# APM32F070 register map
File version: 1.0
Registers are 32-bit, read-write, reset 0x0 unless marked. A register's access mark holds for its fields unless they carry their own. Offsets are from the block's base; [hi:lo] are bit positions; {n}, {i} and the like mark numbered series.

## TMR6 — Basic-timers
Base 0x40001000
Same registers: TMR7 0x40001400
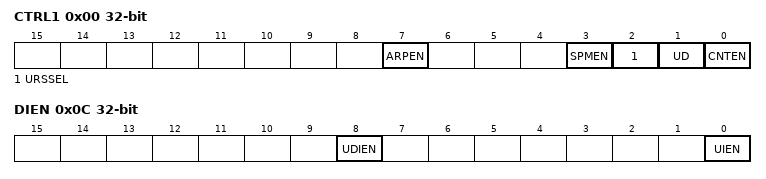
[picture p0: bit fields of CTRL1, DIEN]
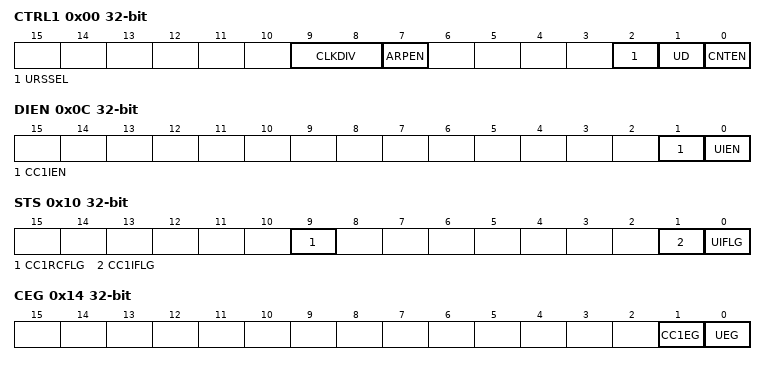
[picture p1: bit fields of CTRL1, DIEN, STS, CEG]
0x00 CTRL1 — control register 1
  [7] ARPEN — Auto-reload preload enable
  [3] SPMEN — One-pulse mode
  [2] URSSEL — Update request source
  [1] UD — Update disable
  [0] CNTEN — Counter enable
0x04 CTRL2 — control register 2
  [6:4] MMSEL — Master mode selection
0x0C DIEN — DMA/Interrupt enable register
  [8] UDIEN — Update DMA request enable
  [0] UIEN — Update interrupt enable
0x10 STS — status register
  [0] UIFLG — Update interrupt flag
0x14 CEG wo — event generation register
  [0] UEG — Update generation
0x24 CNT — counter
  [15:0] CNT — Low counter value
0x28 PSC — prescaler
  [15:0] PSC — Prescaler value
0x2C AUTORLD reset 0xFFFF — auto-reload register
  [15:0] AUTORLD — Low Auto-reload value

## TMR14 — General-purpose-timers
Base 0x40002000
0x00 CTRL1 — control register 1
  [9:8] CLKDIV — Clock division
  [7] ARPEN — Auto-reload preload enable
  [2] URSSEL — Update request source
  [1] UD — Update disable
  [0] CNTEN — Counter enable
0x0C DIEN — DMA/Interrupt enable register
  [1] CC1IEN — Capture/Compare 1 interrupt enable
  [0] UIEN — Update interrupt enable
0x10 STS — status register
  [9] CC1RCFLG — Capture/Compare 1 overcapture flag
  [1] CC1IFLG — Capture/compare 1 interrupt flag
  [0] UIFLG — Update interrupt flag
0x14 CEG wo — event generation register
  [1] CC1EG — Capture/compare 1 generation
  [0] UEG — Update generation
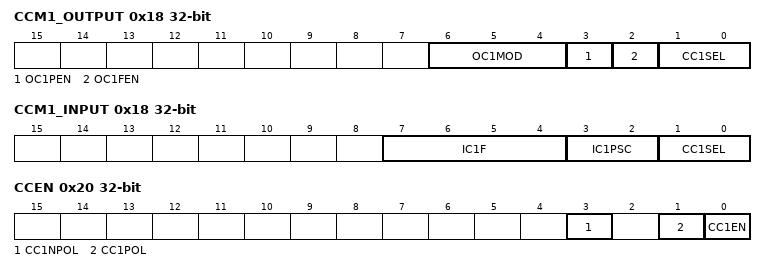
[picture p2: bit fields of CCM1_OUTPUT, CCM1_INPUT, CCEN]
0x18 CCM1_OUTPUT — capture/compare mode register (output mode)
  [6:4] OC1MOD — Output Compare 1 mode
  [3] OC1PEN — Output Compare 1 preload enable
  [2] OC1FEN — Output Compare 1 fast enable
  [1:0] CC1SEL — Capture/Compare 1 selection
0x18 CCM1_INPUT (alternate view of CCM1_OUTPUT) — capture/compare mode register 1 (input mode)
  [7:4] IC1F — Input capture 1 filter
  [3:2] IC1PSC — Input capture 1 prescaler
  [1:0] CC1SEL — Capture/Compare 1 selection
0x20 CCEN — capture/compare enable register
  [3] CC1NPOL — Capture/Compare 1 output Polarity
  [1] CC1POL — Capture/Compare 1 output Polarity
  [0] CC1EN — Capture/Compare 1 output enable
0x24 CNT — counter
  [15:0] CNT — counter value
0x28 PSC — prescaler
  [15:0] PSC — Prescaler value
0x2C AUTORLD reset 0xFFFF — auto-reload register
  [15:0] AUTORLD — Auto-reload value
0x34 CC1 — capture/compare register 1
  [15:0] CC1 — Capture/Compare 1 value
0x50 OPT — option register
  [1:0] RMPSEL — Timer input 1 remap

## TMR16 — General-purpose-timers
Base 0x40014400
Same registers: TMR17 0x40014800
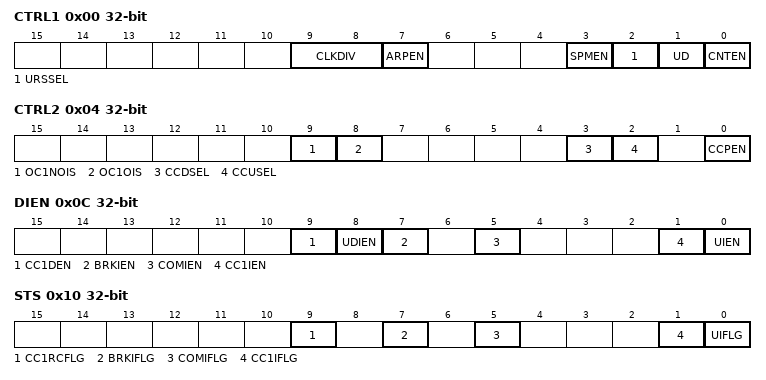
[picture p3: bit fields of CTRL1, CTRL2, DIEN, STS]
0x00 CTRL1 — control register 1
  [9:8] CLKDIV — Clock division
  [7] ARPEN — Auto-reload preload enable
  [3] SPMEN — One-pulse mode
  [2] URSSEL — Update request source
  [1] UD — Update disable
  [0] CNTEN — Counter enable
0x04 CTRL2 — control register 2
  [9] OC1NOIS — Output Idle state 1
  [8] OC1OIS — Output Idle state 1
  [3] CCDSEL — Capture/compare DMA selection
  [2] CCUSEL — Capture/compare control update selection
  [0] CCPEN — Capture/compare preloaded control
0x0C DIEN — DMA/Interrupt enable register
  [9] CC1DEN — Capture/Compare 1 DMA request enable
  [8] UDIEN — Update DMA request enable
  [7] BRKIEN — Break interrupt enable
  [5] COMIEN — COM interrupt enable
  [1] CC1IEN — Capture/Compare 1 interrupt enable
  [0] UIEN — Update interrupt enable
0x10 STS — status register
  [9] CC1RCFLG — Capture/Compare 1 overcapture flag
  [7] BRKIFLG — Break interrupt flag
  [5] COMIFLG — COM interrupt flag
  [1] CC1IFLG — Capture/compare 1 interrupt flag
  [0] UIFLG — Update interrupt flag
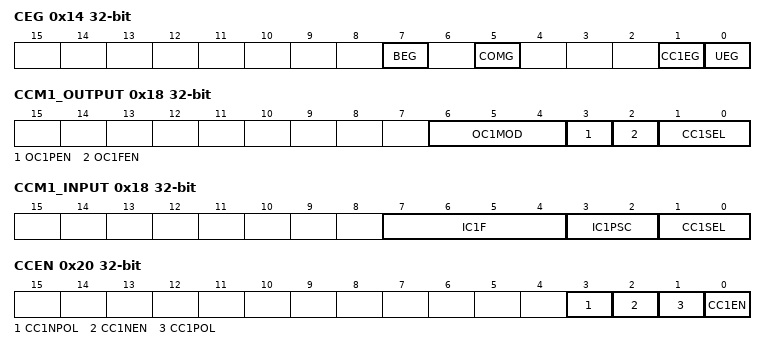
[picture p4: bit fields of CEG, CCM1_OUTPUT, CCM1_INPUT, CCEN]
0x14 CEG wo — event generation register
  [7] BEG — Break generation
  [5] COMG — Capture/Compare control update generation
  [1] CC1EG — Capture/compare 1 generation
  [0] UEG — Update generation
0x18 CCM1_OUTPUT — capture/compare mode register (output mode)
  [6:4] OC1MOD — Output Compare 1 mode
  [3] OC1PEN — Output Compare 1 preload enable
  [2] OC1FEN — Output Compare 1 fast enable
  [1:0] CC1SEL — Capture/Compare 1 selection
0x18 CCM1_INPUT (alternate view of CCM1_OUTPUT) — capture/compare mode register 1 (input mode)
  [7:4] IC1F — Input capture 1 filter
  [3:2] IC1PSC — Input capture 1 prescaler
  [1:0] CC1SEL — Capture/Compare 1 selection
0x20 CCEN — capture/compare enable register
  [3] CC1NPOL — Capture/Compare 1 output Polarity
  [2] CC1NEN — Capture/Compare 1 complementary output enable
  [1] CC1POL — Capture/Compare 1 output Polarity
  [0] CC1EN — Capture/Compare 1 output enable
0x24 CNT — counter
  [15:0] CNT — counter value
0x28 PSC — prescaler
  [15:0] PSC — Prescaler value
0x2C AUTORLD reset 0xFFFF — auto-reload register
  [15:0] AUTORLD — Auto-reload value
0x30 REPCNT — repetition counter register
  [7:0] REPCNT — Repetition counter value
0x34 CC1 — capture/compare register 1
  [15:0] CC1 — Capture/Compare 1 value
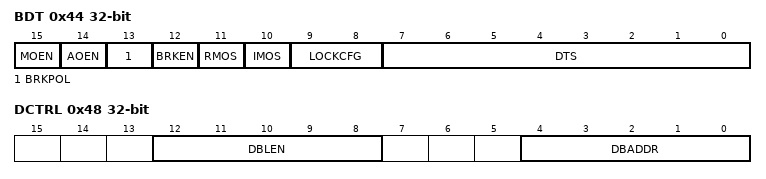
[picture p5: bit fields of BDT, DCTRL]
0x44 BDT — break and dead-time register
  [15] MOEN — Main output enable
  [14] AOEN — Automatic output enable
  [13] BRKPOL — Break polarity
  [12] BRKEN — Break enable
  [11] RMOS — Off-state selection for Run mode
  [10] IMOS — Off-state selection for Idle mode
  [9:8] LOCKCFG — Lock configuration
  [7:0] DTS — Dead-time generator setup
0x48 DCTRL — DMA control register
  [12:8] DBLEN — DMA burst length
  [4:0] DBADDR — DMA base address
0x4C DMADDR — DMA address for full transfer
  [15:0] DMADDR — DMA register for burst accesses

## USBD — Universal Serial BuswFull-SpeedDevice
Base 0x40005C00
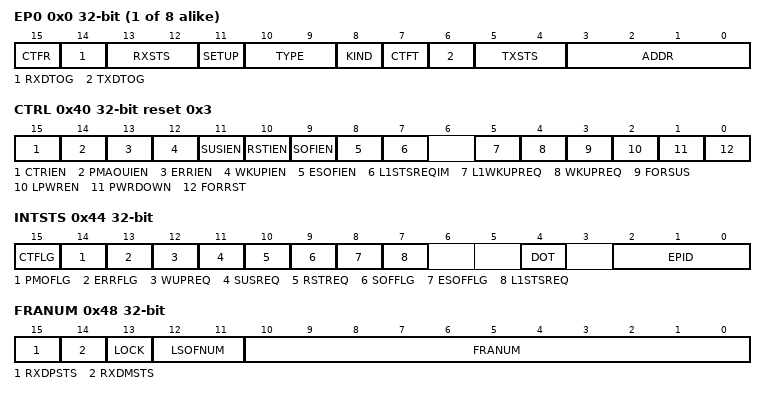
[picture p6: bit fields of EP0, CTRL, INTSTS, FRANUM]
{0x0+4i} EP{i} (i=0..7) — endpoint register {i}
  [15] CTFR — Correct Transfer Flag for Reception
  [14] RXDTOG — Data Toggle for Reception Transfers
  [13:12] RXSTS — Status Bits for Reception Transfers
  [11] SETUP — Setup Transaction Completed
  [10:9] TYPE — Endpoint Type
  [8] KIND — Endpoint Kind
  [7] CTFT — Correct Transfer Flag for Transmission
  [6] TXDTOG — Data Toggle for Transmission Transfers
  [5:4] TXSTS — Status Bits for Transmission Transfers
  [3:0] ADDR — Endpoint Address
0x40 CTRL reset 0x3 — control register
  [15] CTRIEN — Correct Transfer Interrupt Enable
  [14] PMAOUIEN — Packet Memory Area Over / Underrun Interrupt Enable
  [13] ERRIEN — Error Interrupt Enable
  [12] WKUPIEN — Wakeup Interrupt Enable
  [11] SUSIEN — Suspend Mode Interrupt Enable
  [10] RSTIEN — USBD Reset Interrupt Enable
  [9] SOFIEN — Start of Frame Interrupt Enable
  [8] ESOFIEN — Expected Startwof Frame Interrupt Enable
  [7] L1STSREQIM — LPML1 state request interrupt mask
  [5] L1WKUPREQ — LPML1 Wakeup request
  [4] WKUPREQ — Wakeup Request
  [3] FORSUS — Force Suspend
  [2] LPWREN — Lowpower Mode Enable
  [1] PWRDOWN — Power Down
  [0] FORRST — Force USBD Reset
0x44 INTSTS access per field — interrupt status register
  [15] CTFLG ro — Correct Transfer Flag
  [14] PMOFLG rw — Packet Memory Overflow Flag
  [13] ERRFLG rw — Failure Of Transfer Flag
  [12] WUPREQ rw — Wakeup Request
  [11] SUSREQ rw — Suspend Mode Request
  [10] RSTREQ rw — Reset Request
  [9] SOFFLG rw — Start Of Frame Flag
  [8] ESOFFLG rw — Expected Start of Frame Flag
  [7] L1STSREQ rw — LPML1 state request
  [4] DOT ro — Direction of Transaction
  [2:0] EPID ro — Endpoint Identifier
0x48 FRANUM ro — frame number register
  [15] RXDPSTS — Receive Data+ Line Status
  [14] RXDMSTS — Receive Data- line Status
  [13] LOCK
  [12:11] LSOFNUM — Continuous Lost SOF Number
  [10:0] FRANUM — Frame Sequence Number
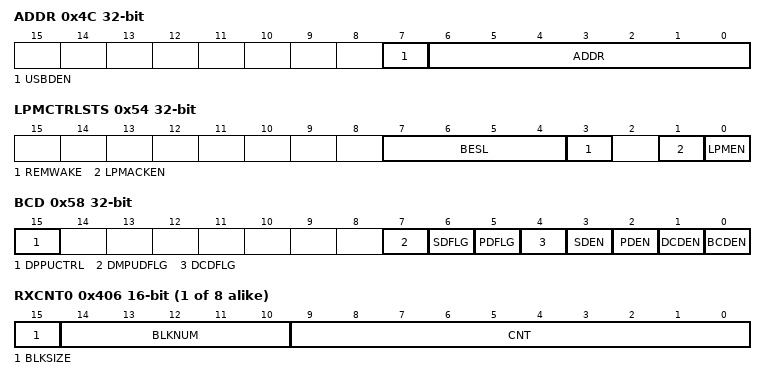
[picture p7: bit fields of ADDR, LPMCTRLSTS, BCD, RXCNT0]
0x4C ADDR — device address
  [7] USBDEN — USBD Enable
  [6:0] ADDR — Device Address
0x50 BUFFTB — Buffer table address
  [15:3] BUFFTB — ADC clock mode
0x54 LPMCTRLSTS access per field — LPM control and status register
  [7:4] BESL ro — BESL Value
  [3] REMWAKE ro — bRemoteWake Value
  [1] LPMACKEN rw — LPM Support Acknowledge Enable
  [0] LPMEN rw — LPM Support Enable
0x58 BCD access per field — Battery charging detector register
  [15] DPPUCTRL rw — DP Pull-up Control
  [7] DMPUDFLG ro — DM Pull-up Detection Status Flag
  [6] SDFLG ro — Secondary Detection Status Flag
  [5] PDFLG ro — Primary Detection Status Flag
  [4] DCDFLG ro — Data Contact Detection Status Flag
  [3] SDEN rw — Secondary Detection Mode Enable
  [2] PDEN rw — Primary Detection Mode Enable
  [1] DCDEN rw — Data Contact Detection ModewEnable
  [0] BCDEN rw — Battery Charging Detector Enable
{0x400+8i} TXADDR{i} 16-bit (i=0..7) — Transmission buffer address register 0
  [15:1] ADDR — Transmission Buffer Address
{0x402+8i} TXCNT{i} 16-bit (i=0..7) — Transmission byte count register 0
  [9:0] CNT — Transmission Byte Count
{0x404+8i} RXADDR{i} 16-bit (i=0..7) — Reception buffer address register 0
  [15:1] ADDR — Reception Buffer Address
{0x406+8i} RXCNT{i} 16-bit access per field (i=0..7) — Transmission byte count register 0
  [15] BLKSIZE rw — Block Size
  [14:10] BLKNUM rw — Number of Blocks
  [9:0] CNT ro — Reception Byte Count
